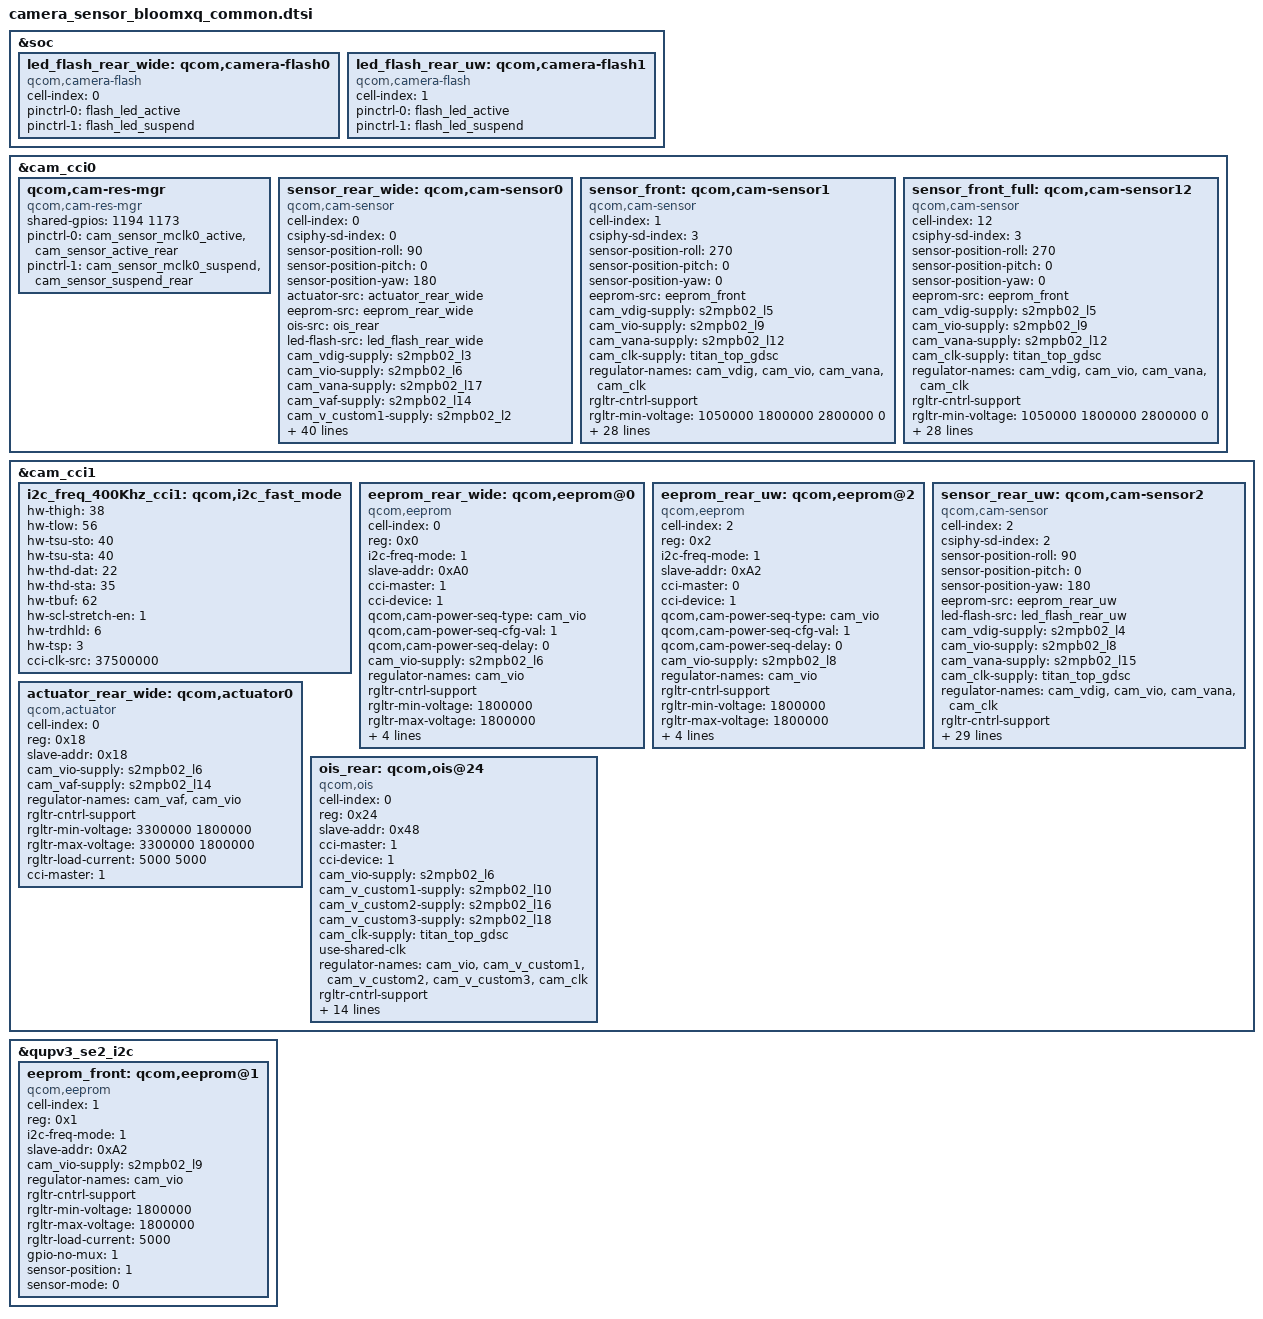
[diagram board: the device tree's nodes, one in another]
&soc {
	led_flash_rear_wide: qcom,camera-flash0 {
		cell-index = <0>;
		compatible = "qcom,camera-flash";
		pinctrl-names = "cam_default", "cam_suspend";
		pinctrl-0 = <&flash_led_active>;
		pinctrl-1 = <&flash_led_suspend>;
		status = "ok";
	};

	led_flash_rear_uw: qcom,camera-flash1 {
		cell-index = <1>;
		compatible = "qcom,camera-flash";
		pinctrl-names = "cam_default", "cam_suspend";
		pinctrl-0 = <&flash_led_active>;
		pinctrl-1 = <&flash_led_suspend>;
		status = "ok";
	};

};

&cam_cci0 {
	qcom,cam-res-mgr {
		compatible = "qcom,cam-res-mgr";
		shared-gpios = <1194 1173>;
		pinctrl-names = "cam_res_mgr_default", "cam_res_mgr_suspend";
		status = "ok";
		pinctrl-0 = <&cam_sensor_mclk0_active &cam_sensor_active_rear>;
		pinctrl-1 = <&cam_sensor_mclk0_suspend &cam_sensor_suspend_rear>;
	};

	sensor_rear_wide: qcom,cam-sensor0 {
		cell-index = <0>;
		compatible = "qcom,cam-sensor";
		csiphy-sd-index = <0>;
		sensor-position-roll = <90>;
		sensor-position-pitch = <0>;
		sensor-position-yaw = <180>;
		actuator-src = <&actuator_rear_wide>;
		eeprom-src = <&eeprom_rear_wide>;
		ois-src = <&ois_rear>;
		led-flash-src = <&led_flash_rear_wide>;
		cam_vdig-supply = <&s2mpb02_l3>;       /* VDD_MAINCAM_1P05 */
		cam_vio-supply = <&s2mpb02_l6>;        /* VDD_MAINCAM_IO_1P8 */
		cam_vana-supply = <&s2mpb02_l17>;      /* VDD_MAINCAM_A2P8 */
		cam_vaf-supply = <&s2mpb02_l14>;       /* VDD_MAINCAM_AF_3P3 */
		cam_v_custom1-supply = <&s2mpb02_l2>;  /* Retention voltage 1.05V */
		cam_v_custom2-supply = <&s2mpb02_l13>; /* Analog voltage 2.4V */
		cam_v_custom3-supply = <&s2mpb02_l1>;  /* DRAM Voltage 1.1V */
		cam_v_custom4-supply = <&s2mpb02_l10>; //VDD_OIS_1P8
		cam_v_custom5-supply = <&s2mpb02_l16>; //VDD_OIS_2P8
		cam_v_custom6-supply = <&s2mpb02_l18>; //VDD_OIS_VM_2P8
		cam_clk-supply = <&titan_top_gdsc>;
		regulator-names = "cam_vdig", "cam_vio", "cam_vana", "cam_vaf", "cam_clk", "cam_v_custom1", "cam_v_custom2", "cam_v_custom3", "cam_v_custom4", "cam_v_custom5", "cam_v_custom6";
		rgltr-cntrl-support;
		rgltr-min-voltage = <1050000 1800000 2800000 3300000 0 1050000 2400000 1100000 1800000 2800000 2800000>;
		rgltr-max-voltage = <1050000 1800000 2800000 3300000 0 1050000 2400000 1100000 1800000 2800000 2800000>;
		rgltr-load-current = <200000 200000 5000 5000 0 5000 5000 5000 5000 5000 5000>;
		gpio-no-mux = <0>;
		use-shared-clk;
		pinctrl-names = "cam_default", "cam_suspend";
		gpios = <&tlmm 94 0>,
		        <&tlmm 73 0>;
		gpio-reset = <1>;
		gpio-req-tbl-num = <0 1>;
		gpio-req-tbl-flags = <1 0>;
		gpio-req-tbl-label = "CAMIF_MCLK0",
					         "CAM_RESET0";
		sensor-mode = <0>;
		cci-master = <0>;
		status = "ok";
		clocks = <&clock_camcc CAM_CC_MCLK0_CLK>;
		clock-names = "cam_clk";
		clock-cntl-level = "turbo";
		clock-rates = <19200000>;

		cam,isp = <0>;                  // 0 : INT , 1 : EXT , 2 : SOC
		cam,cal_memory = <2>;           // 0 : N , 1 : FROM , 2 : EEPROM , 3 : OTP
		cam,read_version = <1>;         // 0 : SYSFS , 1 : CAMON
		cam,core_voltage = <1>;         // 0 : N , 1 : Y
		cam,upgrade = <2>;              // 0 : N , 1 : SYSFS , 2 : CAMON
		cam,fw_write = <3>;             // 0 : N , 1 : OS , 2 : SD , 3 : ALL
		cam,fw_dump = <1>;              // 0 : N , 1 : Y
		cam,companion_chip = <0>;       // 0 : N , 1 : Y
		cam,ois = <1>;                  // 0 : N , 1 : Y
		cam,dual_open = <0>;            // 0 : N , 1 : Y
		cam,valid = <1>;                // 0 : N , 1 : Y
	};

	sensor_front: qcom,cam-sensor1 {
		cell-index = <1>;
		compatible = "qcom,cam-sensor";
		csiphy-sd-index = <3>;
		sensor-position-roll = <270>;
		sensor-position-pitch = <0>;
		sensor-position-yaw = <0>;
		eeprom-src = <&eeprom_front>;
		cam_vdig-supply = <&s2mpb02_l5>;	/* VDD_VT10M_1P05   */
		cam_vio-supply = <&s2mpb02_l9>;		/* VDD_VT10M_IO_1P8 */
		cam_vana-supply = <&s2mpb02_l12>;	/* VDD_VT10M_A2P8   */
		cam_clk-supply = <&titan_top_gdsc>;
		regulator-names = "cam_vdig", "cam_vio", "cam_vana", "cam_clk";
		rgltr-cntrl-support;
		rgltr-min-voltage = <1050000 1800000 2800000 0>;
		rgltr-max-voltage = <1050000 1800000 2800000 0>;
		rgltr-load-current = <200000 200000 5000 0>;
		gpio-no-mux = <0>;
		pinctrl-names = "cam_default", "cam_suspend";
		pinctrl-0 = <&cam_sensor_mclk2_active
				&cam_sensor_active_front>;
		pinctrl-1 = <&cam_sensor_mclk2_suspend
				&cam_sensor_suspend_front>;
		gpios = <&tlmm 96 0>,
			<&tlmm 25 0>;
		gpio-reset = <1>;
		gpio-req-tbl-num = <0 1>;
		gpio-req-tbl-flags = <1 0>;
		gpio-req-tbl-label = "CAMIF_MCLK2",
					"CAM_RESET2";
		sensor-mode = <0>;
		cci-master = <1>;
		status = "ok";
		clocks = <&clock_camcc CAM_CC_MCLK2_CLK>;
		clock-names = "cam_clk";
		clock-cntl-level = "turbo";
		clock-rates = <24000000>;

		cam,isp = <0>;                  // 0 : INT , 1 : EXT , 2 : SOC
		cam,cal_memory = <2>;           // 0 : N , 1 : FROM , 2 : EEPROM , 3 : OTP
		cam,read_version = <0>;         // 0 : SYSFS , 1 : CAMON
		cam,core_voltage = <0>;         // 0 : N , 1 : Y
		cam,upgrade = <0>;              // 0 : N , 1 : SYSFS , 2 : CAMON
		cam,fw_write = <0>;             // 0 : N , 1 : OS , 2 : SD , 3 : ALL
		cam,fw_dump = <0>;              // 0 : N , 1 : Y
		cam,companion_chip = <0>;       // 0 : N , 1 : Y
		cam,ois = <0>;                  // 0 : N , 1 : Y
		cam,dual_open = <0>;            // 0 : N , 1 : Y
		cam,valid = <1>;                // 0 : N , 1 : Y
	};

	sensor_front_full: qcom,cam-sensor12 {
		cell-index = <12>;
		compatible = "qcom,cam-sensor";
		csiphy-sd-index = <3>;
		sensor-position-roll = <270>;
		sensor-position-pitch = <0>;
		sensor-position-yaw = <0>;
		eeprom-src = <&eeprom_front>;
		cam_vdig-supply = <&s2mpb02_l5>;	/* VDD_VT10M_1P05   */
		cam_vio-supply = <&s2mpb02_l9>;		/* VDD_VT10M_IO_1P8 */
		cam_vana-supply = <&s2mpb02_l12>;	/* VDD_VT10M_A2P8   */
		cam_clk-supply = <&titan_top_gdsc>;
		regulator-names = "cam_vdig", "cam_vio", "cam_vana", "cam_clk";
		rgltr-cntrl-support;
		rgltr-min-voltage = <1050000 1800000 2800000 0>;
		rgltr-max-voltage = <1050000 1800000 2800000 0>;
		rgltr-load-current = <200000 200000 5000 0>;
		gpio-no-mux = <0>;
		pinctrl-names = "cam_default", "cam_suspend";
		pinctrl-0 = <&cam_sensor_mclk2_active
				&cam_sensor_active_front>;
		pinctrl-1 = <&cam_sensor_mclk2_suspend
				&cam_sensor_suspend_front>;
		gpios = <&tlmm 96 0>,
			<&tlmm 25 0>;
		gpio-reset = <1>;
		gpio-req-tbl-num = <0 1>;
		gpio-req-tbl-flags = <1 0>;
		gpio-req-tbl-label = "CAMIF_MCLK2",
					"CAM_RESET2";
		sensor-mode = <0>;
		cci-master = <1>;
		status = "ok";
		clocks = <&clock_camcc CAM_CC_MCLK2_CLK>;
		clock-names = "cam_clk";
		clock-cntl-level = "turbo";
		clock-rates = <19200000>;

		cam,isp = <0>;                  // 0 : INT , 1 : EXT , 2 : SOC
		cam,cal_memory = <2>;           // 0 : N , 1 : FROM , 2 : EEPROM , 3 : OTP
		cam,read_version = <0>;         // 0 : SYSFS , 1 : CAMON
		cam,core_voltage = <0>;         // 0 : N , 1 : Y
		cam,upgrade = <0>;              // 0 : N , 1 : SYSFS , 2 : CAMON
		cam,fw_write = <0>;             // 0 : N , 1 : OS , 2 : SD , 3 : ALL
		cam,fw_dump = <0>;              // 0 : N , 1 : Y
		cam,companion_chip = <0>;       // 0 : N , 1 : Y
		cam,ois = <0>;                  // 0 : N , 1 : Y
		cam,dual_open = <0>;            // 0 : N , 1 : Y
		cam,valid = <1>;                // 0 : N , 1 : Y
	};

};

&cam_cci1 {
	/* This node is added to enable the "I2C Clock Stretching" for OIS module */
	i2c_freq_400Khz_cci1: qcom,i2c_fast_mode {
		hw-thigh = <38>;
		hw-tlow = <56>;
		hw-tsu-sto = <40>;
		hw-tsu-sta = <40>;
		hw-thd-dat = <22>;
		hw-thd-sta = <35>;
		hw-tbuf = <62>;
		hw-scl-stretch-en = <1>;
		hw-trdhld = <6>;
		hw-tsp = <3>;
		cci-clk-src = <37500000>;
		status = "ok";
	};

	eeprom_rear_wide: qcom,eeprom@0 {
		cell-index = <0>;
		reg = <0x0>;
		compatible = "qcom,eeprom";
		i2c-freq-mode = <1>;
		slave-addr = <0xA0>;
		//eeprom-name= "cat24c512c8utr";

		cci-master = <1>;
		cci-device = <1>;

		qcom,cam-power-seq-type = "cam_vio";
		qcom,cam-power-seq-cfg-val = <1>;
		qcom,cam-power-seq-delay = <0>;

		cam_vio-supply = <&s2mpb02_l6>; /* VDD_MAINCAM_IO_1P8 */
		regulator-names = "cam_vio";
		rgltr-cntrl-support;
		rgltr-min-voltage = <1800000>;
		rgltr-max-voltage = <1800000>;
		rgltr-load-current = <5000>;
		gpio-no-mux = <1>;
		sensor-position = <0>;
		sensor-mode = <0>;
		status = "ok";
	};

	eeprom_rear_uw: qcom,eeprom@2 { /* Ultra Wide */
		cell-index = <2>;
		reg = <0x2>;
		compatible = "qcom,eeprom";
		i2c-freq-mode = <1>;
		slave-addr = <0xA2>;
		//eeprom-name= "gt24p128ca2";

		cci-master = <0>;
		cci-device = <1>;

		qcom,cam-power-seq-type = "cam_vio";
		qcom,cam-power-seq-cfg-val = <1>;
		qcom,cam-power-seq-delay = <0>;

		cam_vio-supply = <&s2mpb02_l8>; /* VDD_MAINCAM_IO_1P8 */
		regulator-names = "cam_vio";
		rgltr-cntrl-support;
		rgltr-min-voltage = <1800000>;
		rgltr-max-voltage = <1800000>;
		rgltr-load-current = <5000>;
		gpio-no-mux = <1>;
		sensor-position = <0>;
		sensor-mode = <0>;
		status = "ok";
	};

	sensor_rear_uw: qcom,cam-sensor2 {
		cell-index = <2>;
		compatible = "qcom,cam-sensor";
		csiphy-sd-index = <2>;
		sensor-position-roll = <90>;
		sensor-position-pitch = <0>;
		sensor-position-yaw = <180>;
		eeprom-src = <&eeprom_rear_uw>;
		led-flash-src = <&led_flash_rear_uw>;
		cam_vdig-supply = <&s2mpb02_l4>;		/* VDD_SWCAM_1P05   */
		cam_vio-supply = <&s2mpb02_l8>;			/* VDD_SWCAM_IO_1P8 */
		cam_vana-supply = <&s2mpb02_l15>;		/* VDD_SWCAM_A2P8   */
		cam_clk-supply = <&titan_top_gdsc>;
		regulator-names = "cam_vdig", "cam_vio", "cam_vana", "cam_clk";
		rgltr-cntrl-support;
		rgltr-min-voltage = <1050000 1800000 2800000 0>;
		rgltr-max-voltage = <1050000 1800000 2800000 0>;
		rgltr-load-current = <200000 200000 5000 0>;
		gpio-no-mux = <0>;
		pinctrl-names = "cam_default", "cam_suspend";
		pinctrl-0 = <&cam_sensor_mclk1_active
			&cam_sensor_active_rear_aux>;
		pinctrl-1 = <&cam_sensor_mclk1_suspend
			&cam_sensor_suspend_rear_aux>;
		gpios = <&tlmm 95 0>,
			<&tlmm 74 0>;
		gpio-reset = <1>;
		gpio-req-tbl-num = <0 1>;
		gpio-req-tbl-flags = <1 0>;
		gpio-req-tbl-label = "CAMIF_MCLK1",
				"CAM_RESET1";
		sensor-mode = <0>;
		cci-master = <0>;
		status = "ok";
		clocks = <&clock_camcc CAM_CC_MCLK1_CLK>;
		clock-names = "cam_clk";
		clock-cntl-level = "turbo";
		clock-rates = <19200000>;

		cam,isp = <0>;                  // 0 : INT , 1 : EXT , 2 : SOC
		cam,cal_memory = <2>;           // 0 : N , 1 : FROM , 2 : EEPROM , 3 : OTP
		cam,read_version = <0>;         // 0 : SYSFS , 1 : CAMON
		cam,core_voltage = <0>;         // 0 : N , 1 : Y
		cam,upgrade = <0>;              // 0 : N , 1 : SYSFS , 2 : CAMON
		cam,fw_write = <0>;             // 0 : N , 1 : OS , 2 : SD , 3 : ALL
		cam,fw_dump = <0>;              // 0 : N , 1 : Y
		cam,companion_chip = <0>;       // 0 : N , 1 : Y
		cam,ois = <0>;                  // 0 : N , 1 : Y
		cam,dual_open = <0>;            // 0 : N , 1 : Y
		cam,valid = <1>;                // 0 : N , 1 : Y
	};

	actuator_rear_wide: qcom,actuator0 {
		cell-index = <0>;
		compatible = "qcom,actuator";
		reg = <0x18>;
		slave-addr = <0x18>;
		cam_vio-supply = <&s2mpb02_l6>;        /* VDD_MAINCAM_IO_1P8 */
		cam_vaf-supply = <&s2mpb02_l14>;       /* VDD_MAINCAM_AF_3P3 */
		regulator-names = "cam_vaf", "cam_vio";
		rgltr-cntrl-support;
		rgltr-min-voltage = <3300000 1800000>;
		rgltr-max-voltage = <3300000 1800000>;
		rgltr-load-current = <5000 5000>;
		cci-master = <1>;
		status = "ok";
	};

	ois_rear: qcom,ois@24  {
		compatible = "qcom,ois";
		cell-index = <0>;
		reg = <0x24>;
		slave-addr = <0x48>;
		cci-master = <1>;
		cci-device = <1>;
		cam_vio-supply = <&s2mpb02_l6>;             //VDD_MAINCAM_IO_1P8
		cam_v_custom1-supply = <&s2mpb02_l10>;      // VDD_OIS_1P8
		cam_v_custom2-supply = <&s2mpb02_l16>;      // VDD_OIS_2P8
		cam_v_custom3-supply = <&s2mpb02_l18>;      // VDD_OIS_VM_2P8
		cam_clk-supply = <&titan_top_gdsc>;
		use-shared-clk;

		regulator-names = "cam_vio", "cam_v_custom1","cam_v_custom2","cam_v_custom3","cam_clk";
		rgltr-cntrl-support;
		rgltr-min-voltage = <1800000 1800000 2800000 2800000 0>;
		rgltr-max-voltage = <1800000 1800000 2800000 2800000 0>;
		rgltr-load-current = <5000 5000 5000 5000 0>;
		gpio-no-mux = <0>;

		gpios = <&tlmm 94 0>,
				 <&tlmm 73 0>;
		gpio-reset = <1>;
		gpio-req-tbl-num = <0 1>;
		gpio-req-tbl-flags = <1 0>;
		gpio-req-tbl-label = "CAMIF_MCLK0","CAM_RESET0";

		clocks = <&clock_camcc CAM_CC_MCLK0_CLK>;
		clock-names = "cam_clk";
		clock-cntl-level = "turbo";
		clock-rates = <19200000>;

		status = "ok";
	};
};

&qupv3_se2_i2c {
	status = "ok";

	eeprom_front: qcom,eeprom@1 {
		cell-index = <1>;
		reg = <0x1>;
		compatible = "qcom,eeprom";
		i2c-freq-mode = <1>;
		slave-addr = <0xA2>;

		cam_vio-supply = <&s2mpb02_l9>;
		regulator-names = "cam_vio";
		rgltr-cntrl-support;
		rgltr-min-voltage = <1800000>;
		rgltr-max-voltage = <1800000>;
		rgltr-load-current = <5000>;
		gpio-no-mux = <1>;
		sensor-position = <1>;
		sensor-mode = <0>;
		status = "ok";
	};
};
